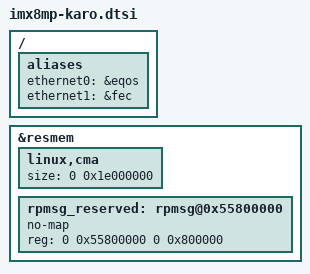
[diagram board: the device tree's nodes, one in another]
// SPDX-License-Identifier: (GPL-2.0 OR MIT)
/*
 * Copyright (C) 2020 Lothar Waßmann <LW@KARO-electronics.de>
 *
 */

#include "imx8mp.dtsi"

/ {
	aliases {
		ethernet0 = &eqos;
		ethernet1 = &fec;
	};
};

&resmem {
	/* overwrite freescale cma setting since it's not allocatable on qsxp */
	linux,cma {
		size = <0 0x1e000000>;
		/delete-property/ alloc-ranges;
	};

	rpmsg_reserved: rpmsg@0x55800000 {
		no-map;
		reg = <0 0x55800000 0 0x800000>;
	};
};
